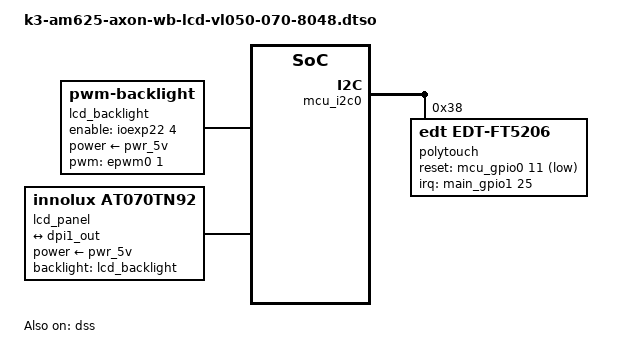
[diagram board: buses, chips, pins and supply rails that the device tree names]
// SPDX-License-Identifier: GPL-2.0-only OR MIT
/*
 * Copyright (C) 2024 TechNexion Ltd.
 *
 * Author: Ray Chang <ray.chang@technexion.com>
 *
 */

/dts-v1/;
/plugin/;

#include <dt-bindings/gpio/gpio.h>
#include <dt-bindings/interrupt-controller/irq.h>

&{/} {
	lcd_backlight: lcd_backlight {
		compatible = "pwm-backlight";
		enable-gpios = <&ioexp22 4 GPIO_ACTIVE_HIGH>;
		power-supply = <&pwr_5v>;
		pwms = <&epwm0 1 50000 0>;
		brightness-levels = <7 255>;
		num-interpolated-steps = <248>;
		default-brightness-level = <100>;
	};

	lcd_panel {
		compatible = "innolux,at070tn92";
		backlight = <&lcd_backlight>;
		power-supply = <&pwr_5v>;

		port {
			panel_lcd_in: endpoint {
				remote-endpoint = <&dpi1_out>;
			};
		};
	};
};

&dss {
	pinctrl-names = "default";
	pinctrl-0 = <&main_dss0_pins_default>;
	status = "okay";
};

&dss_ports {
	#address-cells = <1>;
	#size-cells = <0>;

	/* VP2: DPI Output */
	port@1 {
		reg = <1>;

		dpi1_out: endpoint {
			remote-endpoint = <&panel_lcd_in>;
		};
	};
};

/* I2C_C */
&mcu_i2c0 {
	#address-cells = <1>;
	#size-cells = <0>;

	polytouch: edt-ft5x06@38 {
		compatible = "edt,edt-ft5206";
		reg = <0x38>;
		pinctrl-names = "default";
		pinctrl-0 = <&touch_intr_pins_default &touch_nrst_pins_default>;
		reset-gpios = <&mcu_gpio0 11 GPIO_ACTIVE_LOW>; /* TOUCH_nRST, GPIO_X2_P20 */
		interrupt-parent = <&main_gpio1>; /* TOUCH_nINT, GPIO_X2_P24 */
		interrupts = <25 IRQ_TYPE_EDGE_FALLING>;
		touchscreen-size-x = <800>;
		touchscreen-size-y = <480>;
	};
};
